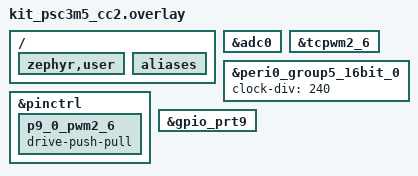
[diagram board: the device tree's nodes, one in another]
/*
 * SPDX-License-Identifier: Apache-2.0
 *
 * PSOC Control CAN Command & Telemetry lab - devicetree overlay
 * (skeleton) for KIT_PSC3M5_CC2, the MCU card fitted to the
 * KIT_PSC3M5_MC1 motor-control kit.
 *
 * This overlay is shared by both roles (Command node and Telemetry node) -
 * the physical board is identical either way, only the application code
 * built on top of it differs.
 *
 * ---------------------------------------------------------------------
 * SAFETY - read this before running the lab on KIT_PSC3M5_CC2
 * ---------------------------------------------------------------------
 * The PWM output you enable in TODO 1c is on P9.0, which is schematic net
 * V2_H: the motor 2, phase V, high-side gate drive, brought out on Power
 * Board Connector X19. With no power board attached, X19 is just an access
 * header and the pin is safe to drive and to probe.
 *
 * NEVER run this lab with a motor-control power board fitted. The lab
 * would be commanding a gate driver.
 *
 * CAN is already enabled by default in this board's base devicetree
 * (kit_psc3m5_cc2-common.dtsi enables can1, and `zephyr,canbus` is already
 * chosen). Unlike KIT_PSC3M5_EVK, this board needs no transceiver node at
 * all - see the note at the end of this file, which is worth reading. Your
 * two devicetree touchpoints in this lab are:
 *
 *   TODO 1a/1b: enable the onboard potentiometer's ADC channel.
 *   TODO 1c:    enable the PWM output used for the brightness command
 *               signal (pin P9.0, on connector X19).
 *
 * Reference: tests/drivers/adc/adc_api/boards/kit_psc3m5_cc2.overlay in the
 * Zephyr tree shows this board's ADC channels fully enabled, and
 * samples/basic/fade_led/boards/kit_psc3m5_evk.overlay shows the equivalent
 * PWM wiring on the sister board, if you get stuck.
 *
 * Docs: what an overlay is and why it exists
 *   https://docs.zephyrproject.org/latest/build/dts/intro.html
 * Every property you can legally set on a node is defined by its binding,
 * and all of the in-tree bindings are published here - searching this page
 * for a `compatible` string is the fastest way to answer "what goes in
 * this node?":
 *   https://docs.zephyrproject.org/latest/build/dts/api/bindings.html
 */

#include <zephyr/dt-bindings/adc/adc.h>
#include <zephyr/dt-bindings/gpio/gpio.h>
#include <zephyr/dt-bindings/pwm/pwm.h>
#include <zephyr/dt-bindings/pwm/pwm_ifx_tcpwm.h>

/ {
	/*
	 * TODO 1a: Uncomment the io-channels property below so the
	 * application can request the potentiometer channel by name. POT1 is
	 * wired to HPPASS SAR ADC channel 12 (this is "CYBSP_POT" in the
	 * ModusToolbox BSP for this board). The second pot, POT2, is on
	 * channel 16 and is not used by this lab.
	 *
	 * Docs: how `io-channels` ties an application to an ADC channel, and
	 * what ADC_DT_SPEC_GET() does with it:
	 *   https://docs.zephyrproject.org/latest/hardware/peripherals/adc.html
	 */
	zephyr,user {
		// io-channels = <&adc0 12>;
	};

	aliases {
		/*
		 * TODO 1c (cont'd): alias the PWM LED node below so the
		 * application's DT_ALIAS(cmd_pwm) resolves.
		 */
		// cmd-pwm = &pwm_cmd;
	};

	/*
	 * TODO 1c (cont'd): uncomment this whole "pwmleds" block (and give
	 * it a real "pwms" property) once tcpwm2_6/pwm2_6 below are enabled.
	 * A pwm-leds node with no "pwms" property fails devicetree
	 * validation, so it must stay fully commented out until then.
	 *
	 * Note this PWM does not reach an on-board LED on this board. The
	 * user LEDs are on P9.4/P9.5, whose only non-GPIO routes are SCB0
	 * SPI selects, so there is no TCPWM path to them. Probe P9.0 on X19,
	 * or hang a 2-pin LED harness off it. The on-board LED in this lab
	 * is driven by software PWM instead, which on this board is the
	 * correct choice rather than a workaround.
	 *
	 * pwmleds {
	 *	compatible = "pwm-leds";
	 *
	 *	pwm_cmd: pwm_cmd_led {
	 *		label = "Command PWM output (P9.0 / V2_H on X19)";
	 *		pwms = <&pwm2_6 0 PWM_USEC(1000) PWM_POLARITY_NORMAL>;
	 *	};
	 * };
	 */
};

&adc0 {
	/*
	 * TODO 1a (cont'd): enable the HPPASS SAR ADC controller itself.
	 */
	// status = "okay";
	#address-cells = <1>;
	#size-cells = <0>;

	/*
	 * TODO 1b: describe ADC channel 12 (12-bit resolution, internal
	 * reference, default acquisition time). Uncomment the block below.
	 *
	 * Docs: the `zephyr,gain` / `zephyr,reference` / `zephyr,resolution`
	 * properties are generic ADC channel properties, explained here:
	 *   https://docs.zephyrproject.org/latest/hardware/peripherals/adc.html
	 */
	// channel@c {
	// 	reg = <12>;
	// 	zephyr,acquisition-time = <ADC_ACQ_TIME_DEFAULT>;
	// 	zephyr,gain = "ADC_GAIN_1";
	// 	zephyr,reference = "ADC_REF_INTERNAL";
	// 	zephyr,resolution = <12>;
	// };
};

&tcpwm2_6 {
	/*
	 * TODO 1c (cont'd): enable this TCPWM instance and its pwm2_6
	 * child, and route it out to pin P9.0 (connector X19).
	 *
	 * P9.0 was chosen because it is one of the few free pins on this
	 * board with a direct TCPWM route - P9_0_TCPWM0_LINE518 is HSIOM
	 * option 10, so no PERI trigger mux is needed. The obvious
	 * alternative, the mikroBUS PWM pin (P0.1), has no TCPWM option at
	 * all.
	 *
	 * Docs: the PWM subsystem and its devicetree model
	 *   https://docs.zephyrproject.org/latest/hardware/peripherals/pwm.html
	 */
	// status = "okay";

	// pwm2_6: pwm2_6 {
	// 	status = "okay";
	// 	clocks = <&peri0_group5_16bit_0>;
	// 	pinctrl-0 = <&p9_0_pwm2_6>;
	// 	pinctrl-names = "default";
	// };
};

/*
 * Provided for you - not a lab task.
 *
 * tcpwm2_6 sits in peripheral group 5, the same group the KIT_PSC3M5_EVK
 * overlay uses for its tcpwm1_4. The divider is shared with &csg0, which the
 * board dtsi sets to 2.
 *
 * 240 divides the 240 MHz peripheral clock to a 1 MHz counter, giving the
 * 1 kHz PWM above exactly 1000 brightness steps.
 *
 * This replaces an earlier 9600 (25 kHz counter, 50 Hz PWM). 50 Hz was slow
 * enough to see: measured on hardware 2026-10-02, the output flashed brightly
 * whenever the duty cycle changed quickly, because one disturbed period lasts
 * a full 20 ms. The TCPWM itself was cleared of blame first - CC0 and CC0_BUFF
 * tracked every request exactly and the counter was never restarted - so the
 * fix is the frequency, not the driver. At 1 kHz the same fade is smooth. */
&peri0_group5_16bit_0 {
	status = "okay";
	clock-div = <240>;
};

&pinctrl {
	p9_0_pwm2_6: p9_0_pwm2_6 {
		drive-push-pull;
	};
};

/* P9.0 (the PWM output) and P9.4/P9.5 (the user LEDs). */
&gpio_prt9 {
	status = "okay";
};

/*
 * Provided for you - not a lab task, but worth understanding.
 *
 * There is deliberately no `phys` property on &can1 and no transceiver node
 * anywhere in this file, and that is a real difference from KIT_PSC3M5_EVK
 * rather than an omission.
 *
 * The CAN front end on this board is galvanically isolated and has one more
 * link in the chain than the EVK:
 *
 *   P6.3 CAN1_TX --> INA  ==||== OUTA --> TXD --+ TLE9371VSJ +-- CANH
 *   P6.2 CAN1_RX <-- OUTB ==||== INB  <-- RXD --+  STB = GND +-- CANL
 *                     2DIB1400F
 *                  dual digital isolator
 *
 * The TLE9371VSJ STB (standby) pin is tied directly to the isolated ground.
 * STB is active high, so the transceiver is permanently in normal mode and
 * there is nothing for software to enable. Adding a can-transceiver-gpio
 * node here would be describing hardware that does not exist.
 *
 * On KIT_PSC3M5_EVK the equivalent STB pin sits on P7.6 with an internal
 * pull-up and nothing releases it, so that board does need a transceiver
 * node - without one it goes bus-off about a millisecond after boot with
 * its error counters still reading zero. Compare the two overlays: this is
 * a good illustration of why devicetree describes the board rather than the
 * chip.
 */
